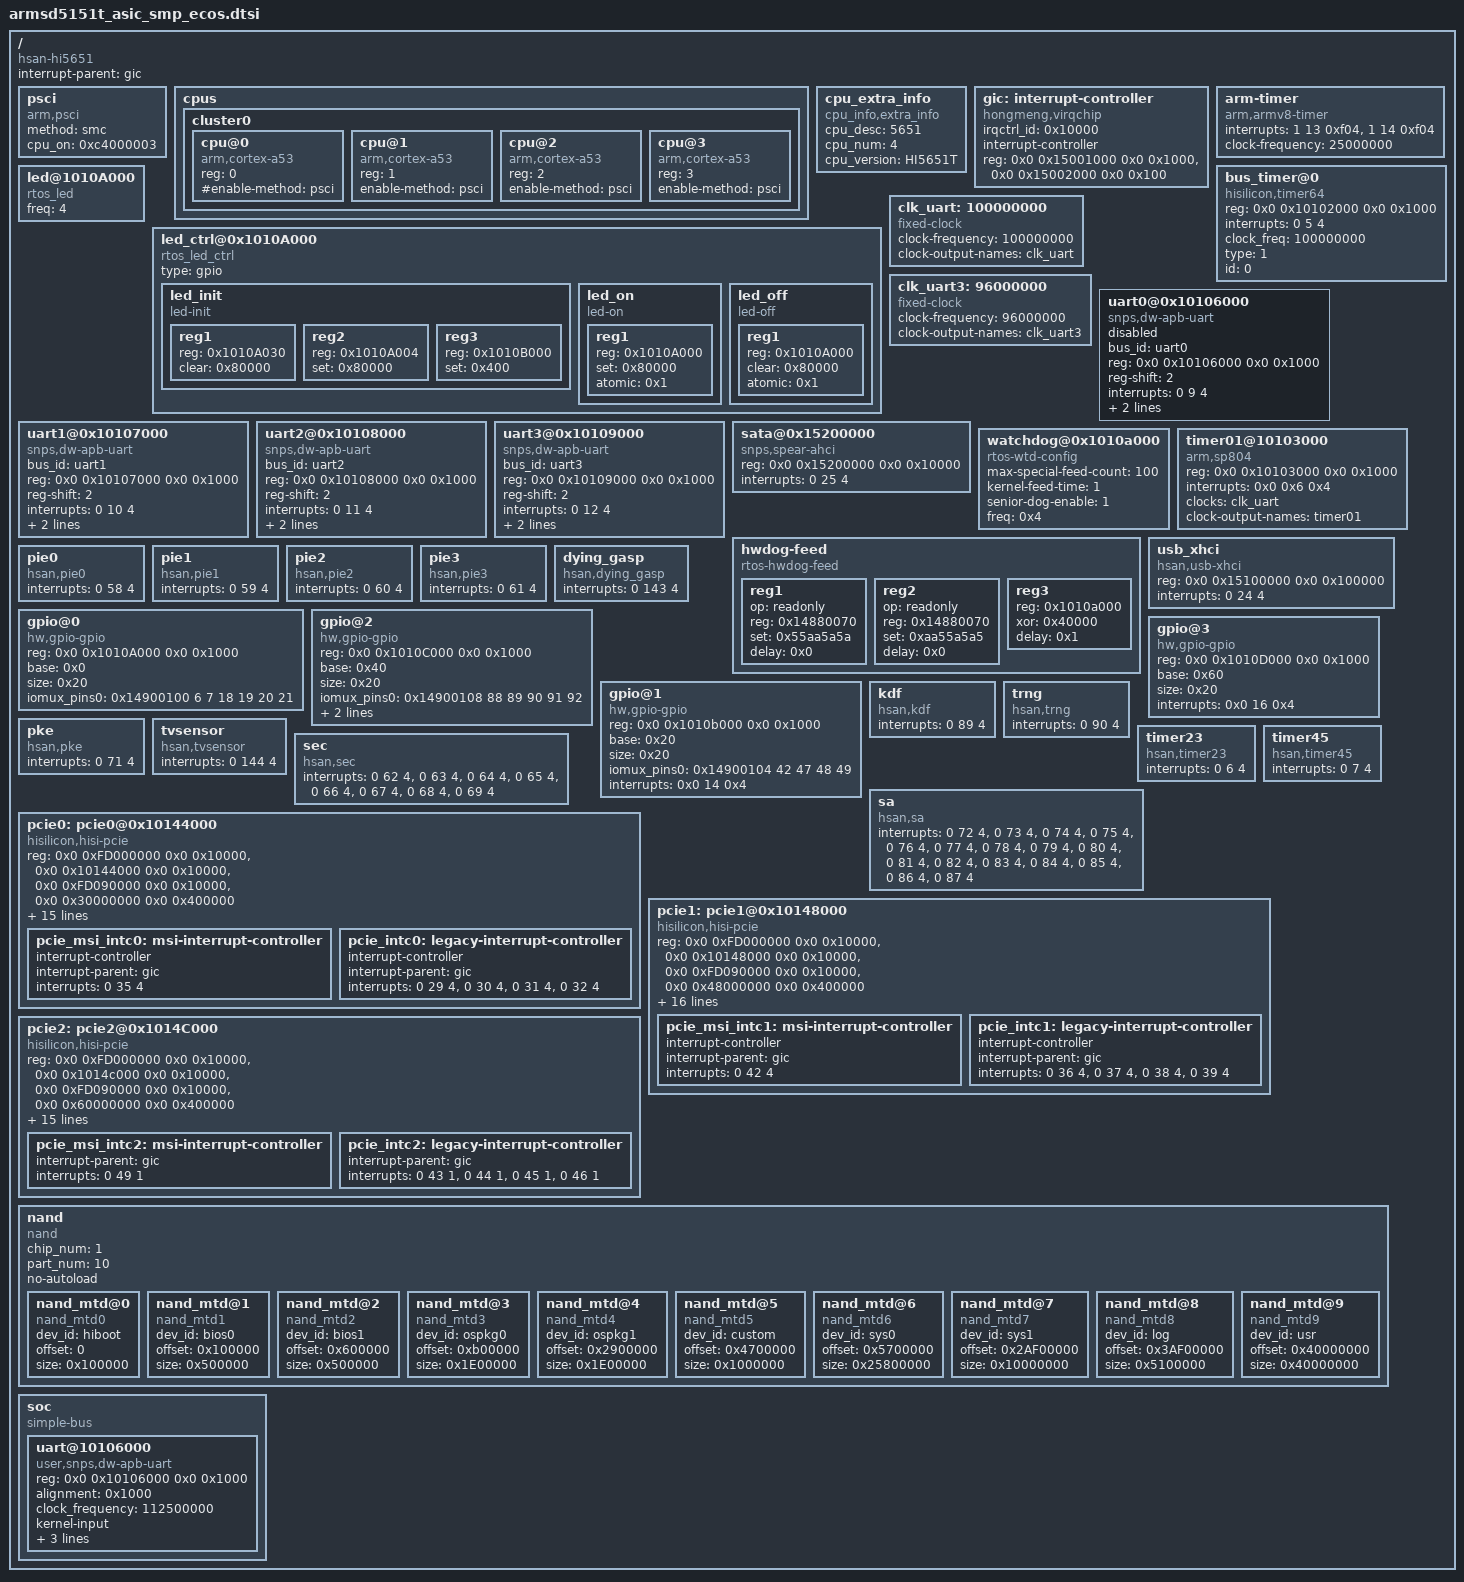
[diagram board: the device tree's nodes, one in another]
/*
 * dts file for Hisilicon hi5651 Development Board
 *
 * Copyright (C) 2016, Hisilicon Ltd.
 *
 */



/ {
    compatible = "hsan-hi5651";
    #address-cells = <2>;
    #size-cells = <2>;
    interrupt-parent = <&gic>;
    psci {
        compatible = "arm,psci";
        method = "smc";
        cpu_on = <0xc4000003>;
    };

    cpus {
        cluster0: cluster0 {
            #address-cells = <1>;
            #size-cells = <0>;

            /* cooling options */
            #cooling-cells = <2>; /* min followed by max */

            cpu@0 {
                compatible = "arm,cortex-a53";
                device_type = "cpu";
                reg = <0>;
                #enable-method = "psci";
            };
            cpu@1 {
                compatible = "arm,cortex-a53";
                device_type = "cpu";
                reg = <1>;
                enable-method = "psci";
            };

            cpu@2 {
                compatible = "arm,cortex-a53";
                device_type = "cpu";
                reg = <2>;
                enable-method = "psci";
            };
            cpu@3 {
                compatible = "arm,cortex-a53";
                device_type = "cpu";
                reg = <3>;
                enable-method = "psci";
            };

        }; /* cluster0 */
    }; /* cpus */

    cpu_extra_info {
        compatible = "cpu_info,extra_info";
        cpu_desc = "5651";
        cpu_num = <4>;
        cpu_version = "HI5651T";
    };

    gic: interrupt-controller {
        compatible = "hongmeng,virqchip";
        irqctrl_id = <0x10000>;
        #interrupt-cells = <0x3>;
        #address-cells = <0x0>;
        interrupt-controller;
        /* gic dist base, gic cpu base */
        reg = <0x0 0x15001000 0x0 0x1000>,
              <0x0 0x15002000 0x0 0x100>;
    };

    arm-timer {
        compatible = "arm,armv8-timer";
        interrupts = <1 13 0xf04>,
                     <1 14 0xf04>;
        clock-frequency = <25000000>;
    };

    bus_timer@0 {
          compatible = "hisilicon,timer64";
          reg = <0x0 0x10102000 0x0 0x1000>;
          interrupts = <0 5 4>;
          clock_freq = <100000000>;
          type = <1>;
          id = <0>;
    };

    led@1010A000 {
         compatible = "rtos_led";
         freq = <4>;
    };
    led_ctrl@0x1010A000 {
       compatible = "rtos_led_ctrl";
       type = "gpio";
       led_init {
              compatible = "led-init";
              #address-cells = <1>;
              #size-cells = <0>;
              reg1 {
                     reg = <0x1010A030>;
                     clear = <0x80000>;
              };
              reg2 {
                     reg = <0x1010A004>;
                     set = <0x80000>;
              };
              reg3 {
                     reg = <0x1010B000>;
                     set = <0x400>;
              };
        };
       led_on {
              compatible = "led-on";
              #address-cells = <1>;
              #size-cells = <0>;
              reg1 {
                     reg = <0x1010A000>;
                     set = <0x80000>;
                     atomic = <0x1>;
              };
       };
       led_off {
              compatible = "led-off";
              #address-cells = <1>;
              #size-cells = <0>;
              reg1 {
                     reg = <0x1010A000>;
                     clear = <0x80000>;
                     atomic = <0x1>;
              };
       };
    };

    clk_uart:100000000{
            compatible = "fixed-clock";
            #clock-cells = <0>;
            clock-frequency = <100000000>;
            clock-output-names = "clk_uart";
        };
      clk_uart3:96000000 {
                compatible = "fixed-clock";
                #clock-cells = <0>;
                clock-frequency = <96000000>;
                clock-output-names = "clk_uart3";
                };

    uart0@0x10106000 {
        compatible = "snps,dw-apb-uart";
                bus_id = "uart0";
        reg = <0x0 0x10106000 0x0 0x1000>;
                reg-shift = <2>;
        interrupts = <0 9 4>;
        clocks = <&clk_uart>;
        clock-names = "apb_pclk";
                tty_name = "ttyAMA";
        status = "disabled";
    };
        uart1@0x10107000 {
                compatible = "snps,dw-apb-uart";
                bus_id = "uart1";
                reg = <0x0 0x10107000 0x0  0x1000>;
                reg-shift = <2>;
                interrupts = <0 10 4>;
                clocks = <&clk_uart>;
                clock-names = "apb_pclk";
                tty_name = "ttyAMA";
        };
        uart2@0x10108000 {
                compatible = "snps,dw-apb-uart";
                bus_id = "uart2";
                reg = <0x0 0x10108000 0x0  0x1000>;
                reg-shift = <2>;
                interrupts = <0 11 4>;
                clocks = <&clk_uart>;
                clock-names = "apb_pclk";
                tty_name = "ttyAMA";
        };
        uart3@0x10109000 {
                compatible = "snps,dw-apb-uart";
                bus_id = "uart3";
                reg = <0x0 0x10109000 0x0 0x1000>;
                reg-shift = <2>;
                interrupts = <0 12 4>;
                clocks = <&clk_uart3>;
                clock-names = "apb_pclk";
                tty_name = "ttyAMA";
        };
        sata@0x15200000{
                compatible = "snps,spear-ahci";
                reg = <0x0 0x15200000 0x0 0x10000>;
                interrupts = <0 25 4>;
        };

        watchdog@0x1010a000{
        compatible = "rtos-wtd-config";
        max-special-feed-count = <100>;
        kernel-feed-time = <1>;
        senior-dog-enable = <1>;
        freq = <0x4>;
    };
    timer01@10103000 {
        compatible = "arm,sp804", "arm,primecell", "arm,sched_clock";
        device_type = "timer_23";
        reg = <0x0 0x10103000 0x0 0x1000>;
        interrupts = <0x0 0x6 0x4>;
        clocks = <&clk_uart>;
        clock-names = "apb_pclk";
        clock-output-names = "timer01";
    };

    hwdog-feed {
        #address-cells = <1>;
        #size-cells = <0>;
        compatible = "rtos-hwdog-feed";
        reg1 {
            op = "readonly";
	    reg = <0x14880070>;
	    set = <0x55aa5a5a>;
            delay = <0x0>;
        };
        reg2 {
            op = "readonly";
	    reg = <0x14880070>;
	    set = <0xaa55a5a5>;
            delay = <0x0>;
        };
        reg3 {
              reg = <0x1010a000>;
            xor = <0x40000>;
            delay = <0x1>;
        };
    };

    usb_xhci{
        reg = <0x0 0x15100000 0x0 0x100000>;
        compatible = "hsan,usb-xhci";
        interrupts = <0 24 4>;   //56
    };

    pie0{
        compatible = "hsan,pie0";
        interrupts = <0 58 4>;   //90
    };

    pie1{
        compatible = "hsan,pie1";
        interrupts = <0 59 4>;   //91
    };

    pie2{
        compatible = "hsan,pie2";
        interrupts = <0 60 4>;   //92
    };

    pie3{
        compatible = "hsan,pie3";
        interrupts = <0 61 4>;   //93
    };

    dying_gasp{
        compatible = "hsan,dying_gasp";
        interrupts = <0 143 4>;  //175
    };

        gpio@0 {
                compatible = "hw,gpio-gpio";
                reg = <0x0 0x1010A000 0x0 0x1000>;
                base = <0x0>;
                size = <0x20>;
                iomux_pins0 = <0x14900100 6 7 18 19 20 21>;
        };

        gpio@2 {
                compatible = "hw,gpio-gpio";
                reg = <0x0 0x1010C000 0x0 0x1000>;
                base = <0x40>;
                size = <0x20>;
                iomux_pins0 = <0x14900108 88 89 90 91 92>;
                iomux_pins1 = <0x14900110 64>;//bit 0
                interrupts = <0x0 15 0x4>;
        };

        gpio@3 {
                compatible = "hw,gpio-gpio";
                reg = <0x0 0x1010D000 0x0 0x1000>;
                base = <0x60>;
                size = <0x20>;
                interrupts = <0x0 16 0x4>;
        };
        gpio@1 {
                compatible = "hw,gpio-gpio";
                reg = <0x0 0x1010b000 0x0 0x1000>;
                base = <0x20>;
                size = <0x20>;
                iomux_pins0 = <0x14900104 42 47 48 49>;
                interrupts = <0x0 14 0x4>;
        };

    kdf{
        compatible = "hsan,kdf";
        interrupts = <0 89 4>;   //121
    };

    trng{
        compatible = "hsan,trng";
        interrupts = <0 90 4>;   //122
    };

    pke{
        compatible = "hsan,pke";
        interrupts = <0 71 4>;   //103
    };

    tvsensor{
        compatible = "hsan,tvsensor";
        interrupts = <0 144 4>;  //176
    };

    timer23{
        compatible = "hsan,timer23";
        interrupts = <0 6 4>;   //38
    };

    timer45{
        compatible = "hsan,timer45";
        interrupts = <0 7 4>;   //39
    };

    sec{
        compatible = "hsan,sec"; //94
        interrupts = <0 62 4>,
                     <0 63 4>,
                     <0 64 4>,
                     <0 65 4>,
                     <0 66 4>,
                     <0 67 4>,
                     <0 68 4>,
                     <0 69 4>;
    };

    sa{
        compatible = "hsan,sa"; //104,tx
        interrupts = <0 72 4>,
                     <0 73 4>,
                     <0 74 4>,
                     <0 75 4>,
                     <0 76 4>,
                     <0 77 4>,
                     <0 78 4>,
                     <0 79 4>,
                     <0 80 4>,
                     <0 81 4>,
                     <0 82 4>,
                     <0 83 4>,
                     <0 84 4>,
                     <0 85 4>,
                     <0 86 4>,
                     <0 87 4>;
    };
    pcie0: pcie0@0x10144000{
        compatible = "hisilicon,hisi-pcie";
        #address-cells = <3>;
        #size-cells = <2>;
        reg = <0x0 0xFD000000 0x0 0x10000>,
            <0x0 0x10144000 0x0 0x10000>,
            <0x0 0xFD090000 0x0 0x10000>,
            <0x0 0x30000000 0x0 0x400000>;
        reg-names = "subctrl", "dbi", "pcs", "config";
        bus-range = <0 9>;
        device_type = "pci";
        dma-coherent;
        ranges = <0x82000000 0x0 0x10000000 0x0 0x20000000 0x0 0x10000000>;
        num-lanes = <2>;
        port-id = <0>;
        port-speed = <2>;
        probe = <0>;
        max-payload = <0>;
        max-read-payload = <0>;
        linux,pci-domain = <7>;
        delay = <10>;
        status = "ok";
        #interrupt-cells = <1>;
        interrupt-map-mask = <0 0 0 7>;
        interrupts = <0 29 1>, <0 35 1>;   /* 61 , 67*/
        interrupt-map = <0 0 0 1 &pcie_intc0 0>, /* INT A */
            <0 0 0 2 &pcie_intc0 1>, /* INT B */
            <0 0 0 3 &pcie_intc0 2>, /* INT C */
            <0 0 0 4 &pcie_intc0 3>; /* INT D */

        pcie_msi_intc0: msi-interrupt-controller {
            interrupt-controller;
            #interrupt-cells = <1>;
            interrupt-parent = <&gic>;
            interrupts = <0 35 4>; //67
            };

        pcie_intc0: legacy-interrupt-controller {
            interrupt-controller;
            #interrupt-cells = <1>;
            interrupt-parent = <&gic>;
            interrupts = <0 29 4>, //61
                <0 30 4>,
                <0 31 4>,
                <0 32 4>;
            };
    };
    pcie1: pcie1@0x10148000{
        compatible = "hisilicon,hisi-pcie";
        #address-cells = <3>;
        #size-cells = <2>;
        reg = <0x0 0xFD000000 0x0 0x10000>,
            <0x0 0x10148000 0x0 0x10000>,
            <0x0 0xFD090000 0x0 0x10000>,
            <0x0 0x48000000 0x0 0x400000>;
        reg-names = "subctrl", "dbi", "pcs", "config";
        bus-range = <10 19>;
        device_type = "pci";
        dma-coherent;
        ranges = <0x82000000 0x0 0x10000000 0x0 0x38000000 0x0 0x10000000>;
        num-lanes = <2>;
        port-id = <1>;
        port-speed = <2>;
        probe = <1>;
        max-payload = <0>;
        max-read-payload = <0>;
        linux,pci-domain = <7>;
        delay = <1000>;
	int-type = <1>; /*0:no int, 1: msi, 2:intx*/
        status = "ok";
        #interrupt-cells = <1>;
        interrupt-map-mask = <0 0 0 7>;
        interrupts = <0 36 1>, <0 42 1>;   /* 68:inta; 74:msi  */
        interrupt-map = <0 0 0 1 &pcie_intc1 0>, /* INT A */
            <0 0 0 2 &pcie_intc1 1>, /* INT B */
            <0 0 0 3 &pcie_intc1 2>, /* INT C */
            <0 0 0 4 &pcie_intc1 3>; /* INT D */

        pcie_msi_intc1: msi-interrupt-controller {
            interrupt-controller;
            #interrupt-cells = <1>;
            interrupt-parent = <&gic>;
            interrupts = <0 42 4>;
            };

        pcie_intc1: legacy-interrupt-controller {
            interrupt-controller;
            #interrupt-cells = <1>;
            interrupt-parent = <&gic>;
            interrupts = <0 36 4>, //68
                <0 37 4>,
                <0 38 4>,
                <0 39 4>;
            };
    };
    pcie2: pcie2@0x1014C000{
        compatible = "hisilicon,hisi-pcie";
        #address-cells = <3>;
        #size-cells = <2>;
        reg = <0x0 0xFD000000 0x0 0x10000>,
            <0x0 0x1014c000 0x0 0x10000>,
            <0x0 0xFD090000 0x0 0x10000>,
            <0x0 0x60000000 0x0 0x400000>;
        reg-names = "subctrl", "dbi", "pcs", "config";
        bus-range = <20 29>;
        device_type = "pci";
        dma-coherent;
        ranges = <0x82000000 0x0 0x10000000 0x0 0x50000000 0x0 0x10000000>;
        num-lanes = <2>;
        port-id = <2>;
        port-speed = <2>;
        probe = <1>;
        max-payload = <0>;
        max-read-payload = <0>;
        linux,pci-domain = <7>;
        delay = <100>;
        status = "ok";
        #interrupt-cells = <1>;
        interrupt-map-mask = <0 0 0 7>;
        interrupts = <0 43 1>, <0 49 1>;   //75:inta; 81:msi
        interrupt-map = <0 0 0 1 &pcie_intc2 0>, /* INT A */
            <0 0 0 2 &pcie_intc2 1>, /* INT B */
            <0 0 0 3 &pcie_intc2 2>, /* INT C */
            <0 0 0 4 &pcie_intc2 3>; /* INT D */

        pcie_msi_intc2: msi-interrupt-controller {
            #interrupt-cells = <1>;
            interrupt-parent = <&gic>;
            interrupts = <0 49 1>; //81
            };

        pcie_intc2: legacy-interrupt-controller {
            #interrupt-cells = <1>;
            interrupt-parent = <&gic>;
            interrupts = <0 43 1>, //75
                <0 44  1>,
                <0 45  1>,
                <0 46  1>;
            };
    };

      nand {
        compatible = "nand";
        chip_num = <1>;
        part_num = <10>;
        /*
         * When the driver name matches the 'compatible' attribute,
         * it will cause the driver to be loaded twice. Add the
         * 'non-autoload' attribute to avoid this situation.
         */
        no-autoload;

        nand_mtd@0 {
            compatible = "nand_mtd0";
            dev_id = "hiboot";
            offset = <0>;
            size = <0x100000>;
        };
        nand_mtd@1 {
            compatible = "nand_mtd1";
            dev_id = "bios0";
            offset = <0x100000>;
            size = <0x500000>;
        };
        nand_mtd@2 {
            compatible = "nand_mtd2";
            dev_id = "bios1";
            offset = <0x600000>;
            size = <0x500000>;
        };
        nand_mtd@3 {
            compatible = "nand_mtd3";
            dev_id = "ospkg0";
            offset = <0xb00000>;
            size = <0x1E00000>;
        };
        nand_mtd@4 {
            compatible = "nand_mtd4";
            dev_id = "ospkg1";
            offset = <0x2900000>;
            size = <0x1E00000>;
        };
        nand_mtd@5 {
            compatible = "nand_mtd5";
            dev_id = "custom";
            offset = <0x4700000>;
            size = <0x1000000>;
        };
        nand_mtd@6 {
            compatible = "nand_mtd6";
                dev_id = "sys0";
                offset = <0x5700000>;
                size = <0x25800000>;
        };
        nand_mtd@7 {
                compatible = "nand_mtd7";
                dev_id = "sys1";
                offset = <0x2AF00000>;
                size = <0x10000000>;
        };
        nand_mtd@8 {
                compatible = "nand_mtd8";
                dev_id = "log";
                offset = <0x3AF00000>;
                size = <0x5100000>;
        };
        nand_mtd@9 {
                compatible = "nand_mtd9";
                dev_id = "usr";
                offset = <0x40000000>;
                size = <0x40000000>;
        };
    };
	soc {
		compatible = "simple-bus";
		#address-cells = <2>;
		#size-cells = <2>;
		ranges;
		/* For user mode uart driver */
                uart@10106000 {
			compatible = "user,snps,dw-apb-uart";
                        reg = <0x0 0x10106000 0x0 0x1000>;
			alignment = <0x1000>;
			clock_frequency = <112500000>; /* 112.5MHz */
			/* kernel control input, must be set in SD5151 */
			kernel-input;
			/* enable fifo */
			fifo-enabled;
			/*
			 * Bit0 and bit1 of flow_state indicate the output and
			 * input status of the serial port, respectively, 1 is
			 * enabled, and 0 is disabled.
			 */
			flow_state = <0x3>;
			no-autoload;
		};
	};
};
